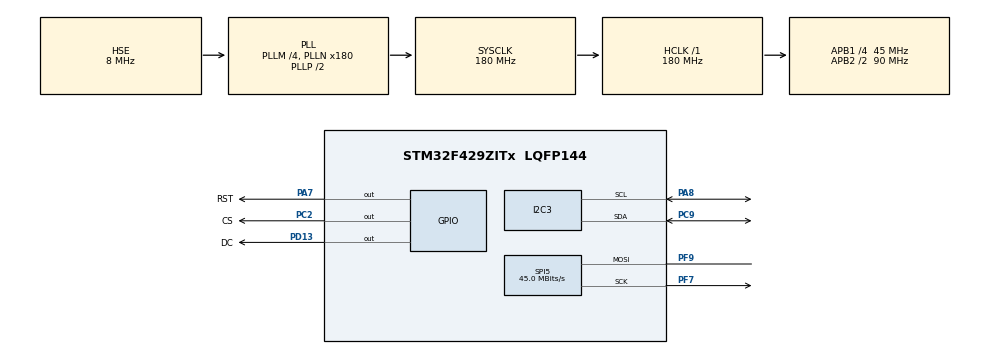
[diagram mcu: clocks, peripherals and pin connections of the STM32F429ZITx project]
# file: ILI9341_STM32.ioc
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Dma.Request0=SPI5_TX
Dma.SPI5_TX.0.Direction=DMA_MEMORY_TO_PERIPH
Dma.SPI5_TX.0.FIFOMode=DMA_FIFOMODE_DISABLE
Dma.SPI5_TX.0.Instance=DMA2_Stream4
Dma.SPI5_TX.0.MemDataAlignment=DMA_MDATAALIGN_BYTE
Dma.SPI5_TX.0.MemInc=DMA_MINC_ENABLE
Dma.SPI5_TX.0.Mode=DMA_NORMAL
Dma.SPI5_TX.0.PeriphDataAlignment=DMA_PDATAALIGN_BYTE
Dma.SPI5_TX.0.PeriphInc=DMA_PINC_DISABLE
Dma.SPI5_TX.0.Priority=DMA_PRIORITY_MEDIUM
Mcu.Family=STM32F4
Mcu.Name=STM32F429ZITx
Mcu.Package=LQFP144
NVIC.DMA2_Stream4_IRQn=true\:0\:0\:false\:false\:true\:false\:true\:true
NVIC.PriorityGroup=NVIC_PRIORITYGROUP_4
NVIC.SPI5_IRQn=true\:0\:0\:false\:false\:true\:true\:true\:true
PA7.GPIO_Label=RST
PA7.Signal=GPIO_Output
PA8.Mode=I2C
PA8.Signal=I2C3_SCL
PC2.GPIO_Label=CS
PC2.Signal=GPIO_Output
PC9.Mode=I2C
PC9.Signal=I2C3_SDA
PD13.GPIO_Label=DC
PD13.Signal=GPIO_Output
PF7.Mode=Simplex_Bidirectional_Master
PF7.Signal=SPI5_SCK
PF9.Mode=Simplex_Bidirectional_Master
PF9.Signal=SPI5_MOSI
PH0/OSC_IN.Mode=HSE-External-Oscillator
PH0/OSC_IN.Signal=RCC_OSC_IN
PH1/OSC_OUT.Mode=HSE-External-Oscillator
PH1/OSC_OUT.Signal=RCC_OSC_OUT
ProjectManager.HeapSize=0x200
ProjectManager.StackSize=0x400
ProjectManager.TargetToolchain=STM32CubeIDE
RCC.48MHZClocksFreq_Value=90000000
RCC.AHBFreq_Value=180000000
RCC.APB1CLKDivider=RCC_HCLK_DIV4
RCC.APB1Freq_Value=45000000
RCC.APB1TimFreq_Value=90000000
RCC.APB2CLKDivider=RCC_HCLK_DIV2
RCC.APB2Freq_Value=90000000
RCC.APB2TimFreq_Value=180000000
RCC.CortexFreq_Value=180000000
RCC.HCLKFreq_Value=180000000
RCC.HSE_VALUE=8000000
RCC.HSI_VALUE=16000000
RCC.LSE_VALUE=32768
RCC.PLLM=4
RCC.PLLN=180
RCC.PLLSourceVirtual=RCC_PLLSOURCE_HSE
RCC.SYSCLKFreq_VALUE=180000000
RCC.SYSCLKSource=RCC_SYSCLKSOURCE_PLLCLK
RCC.VCOOutputFreq_Value=360000000
SPI5.BaudRatePrescaler=SPI_BAUDRATEPRESCALER_2
SPI5.CalculateBaudRate=45.0 MBits/s
SPI5.Direction=SPI_DIRECTION_1LINE
SPI5.FirstBit=SPI_FIRSTBIT_MSB
SPI5.Mode=SPI_MODE_MASTER
SPI5.VirtualType=VM_MASTER
board=custom

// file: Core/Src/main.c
/* USER CODE BEGIN Header */
/**
  ******************************************************************************
  * @file           : main.c
  * @brief          : Main program body
  ******************************************************************************
  * @attention
  *
  * Copyright (c) 2026 STMicroelectronics.
  * All rights reserved.
  *
  * This software is licensed under terms that can be found in the LICENSE file
  * in the root directory of this software component.
  * If no LICENSE file comes with this software, it is provided AS-IS.
  *
  ******************************************************************************
  */
/* USER CODE END Header */
#include <display_lvgl_port.h>
#include <touch_lvgl_port.h>
#include "main.h"
#include "dma.h"
#include "i2c.h"
#include "spi.h"
#include "gpio.h"

/* USER CODE BEGIN Includes */
#include "ILI9341.h"
#include "lvgl.h"
#include "STMPE811.h"
#include "demos/widgets/lv_demo_widgets.h"
#include "demos/benchmark/lv_demo_benchmark.h"
/* USER CODE END Includes */

void SystemClock_Config(void);

int main(void)
{

  /* MCU Configuration--------------------------------------------------------*/

  /* Reset of all peripherals, Initializes the Flash interface and the Systick. */
  HAL_Init();

  /* Configure the system clock */
  SystemClock_Config();

  /* Initialize all configured peripherals */
  MX_GPIO_Init();
  MX_DMA_Init();
  MX_SPI5_Init();
  MX_I2C3_Init();
  /* USER CODE BEGIN 2 */

  lv_init();
  lv_tick_set_cb(HAL_GetTick);
  lv_port_disp_init();
  lv_port_indev_init();
  lv_demo_widgets();
  //lv_demo_benchmark();
  //STMPE811_Touch_Enable();

 // ID=getID();

  /* USER CODE END 2 */

  /* Infinite loop */
  while (1)
  {

    /* USER CODE BEGIN 3 */
	  lv_timer_handler();
	  //HAL_Delay(5);

  }
  /* USER CODE END 3 */
}

void SystemClock_Config(void)
{
  RCC_OscInitTypeDef RCC_OscInitStruct = {0};
  RCC_ClkInitTypeDef RCC_ClkInitStruct = {0};

  /** Configure the main internal regulator output voltage
  */
  __HAL_RCC_PWR_CLK_ENABLE();
  __HAL_PWR_VOLTAGESCALING_CONFIG(PWR_REGULATOR_VOLTAGE_SCALE1);

  /** Initializes the RCC Oscillators according to the specified parameters
  * in the RCC_OscInitTypeDef structure.
  */
  RCC_OscInitStruct.OscillatorType = RCC_OSCILLATORTYPE_HSE;
  RCC_OscInitStruct.HSEState = RCC_HSE_ON;
  RCC_OscInitStruct.PLL.PLLState = RCC_PLL_ON;
  RCC_OscInitStruct.PLL.PLLSource = RCC_PLLSOURCE_HSE;
  RCC_OscInitStruct.PLL.PLLM = 4;
  RCC_OscInitStruct.PLL.PLLN = 180;
  RCC_OscInitStruct.PLL.PLLP = RCC_PLLP_DIV2;
  RCC_OscInitStruct.PLL.PLLQ = 4;
  if (HAL_RCC_OscConfig(&RCC_OscInitStruct) != HAL_OK)
  {
    Error_Handler();
  }

  /** Activate the Over-Drive mode
  */
  if (HAL_PWREx_EnableOverDrive() != HAL_OK)
  {
    Error_Handler();
  }

  /** Initializes the CPU, AHB and APB buses clocks
  */
  RCC_ClkInitStruct.ClockType = RCC_CLOCKTYPE_HCLK|RCC_CLOCKTYPE_SYSCLK
                              |RCC_CLOCKTYPE_PCLK1|RCC_CLOCKTYPE_PCLK2;
  RCC_ClkInitStruct.SYSCLKSource = RCC_SYSCLKSOURCE_PLLCLK;
  RCC_ClkInitStruct.AHBCLKDivider = RCC_SYSCLK_DIV1;
  RCC_ClkInitStruct.APB1CLKDivider = RCC_HCLK_DIV4;
  RCC_ClkInitStruct.APB2CLKDivider = RCC_HCLK_DIV2;

  if (HAL_RCC_ClockConfig(&RCC_ClkInitStruct, FLASH_LATENCY_5) != HAL_OK)
  {
    Error_Handler();
  }
}

void Error_Handler(void)
{
  __disable_irq();
  while (1)
  {
  }
}
